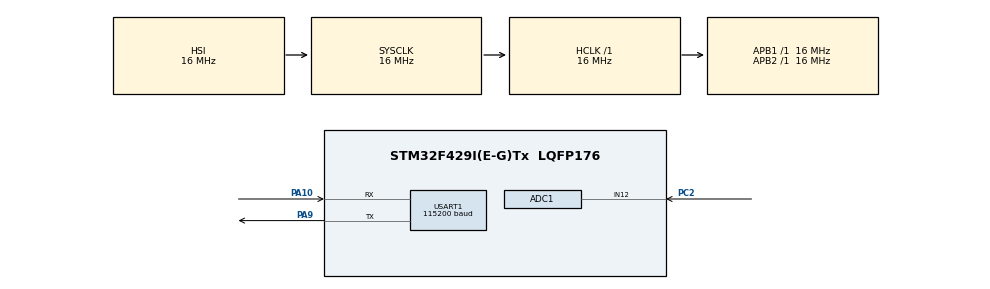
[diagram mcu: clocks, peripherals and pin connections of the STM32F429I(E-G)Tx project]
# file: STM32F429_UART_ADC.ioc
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ADC1.Channel-0\#ChannelRegularConversion=ADC_CHANNEL_12
ADC1.DMAContinuousRequests=ENABLE
ADC1.ExternalTrigConv=ADC_EXTERNALTRIGCONV_T2_TRGO
ADC1.ExternalTrigConvEdge=ADC_EXTERNALTRIGCONVEDGE_RISING
ADC1.NbrOfConversionFlag=1
ADC1.Rank-0\#ChannelRegularConversion=1
ADC1.SamplingTime-0\#ChannelRegularConversion=ADC_SAMPLETIME_84CYCLES
ADC1.master=1
Dma.ADC1.0.Direction=DMA_PERIPH_TO_MEMORY
Dma.ADC1.0.FIFOMode=DMA_FIFOMODE_DISABLE
Dma.ADC1.0.Instance=DMA2_Stream0
Dma.ADC1.0.MemDataAlignment=DMA_MDATAALIGN_HALFWORD
Dma.ADC1.0.MemInc=DMA_MINC_ENABLE
Dma.ADC1.0.Mode=DMA_CIRCULAR
Dma.ADC1.0.PeriphDataAlignment=DMA_PDATAALIGN_HALFWORD
Dma.ADC1.0.PeriphInc=DMA_PINC_DISABLE
Dma.ADC1.0.Priority=DMA_PRIORITY_LOW
Dma.Request0=ADC1
Mcu.Family=STM32F4
Mcu.Name=STM32F429I(E-G)Tx
Mcu.Package=LQFP176
NVIC.ADC_IRQn=true\:0\:0\:false\:false\:true\:true\:true\:true
NVIC.DMA2_Stream0_IRQn=true\:0\:0\:false\:false\:true\:false\:true\:true
NVIC.PriorityGroup=NVIC_PRIORITYGROUP_4
PA10.Mode=Asynchronous
PA10.Signal=USART1_RX
PA13.Mode=Serial_Wire
PA13.Signal=SYS_JTMS-SWDIO
PA14.Mode=Serial_Wire
PA14.Signal=SYS_JTCK-SWCLK
PA9.Mode=Asynchronous
PA9.Signal=USART1_TX
PC2.Signal=ADCx_IN12
ProjectManager.HeapSize=0x200
ProjectManager.StackSize=0x400
ProjectManager.TargetToolchain=MDK-ARM V5.32
RCC.AHBFreq_Value=16000000
RCC.APB1Freq_Value=16000000
RCC.APB2Freq_Value=16000000
RCC.CortexFreq_Value=16000000
RCC.HSE_VALUE=25000000
RCC.HSI_VALUE=16000000
RCC.LSE_VALUE=32768
RCC.SYSCLKFreq_VALUE=16000000
RCC.VCOOutputFreq_Value=192000000
SH.ADCx_IN12.0=ADC1_IN12,IN12
TIM2.Period=999
TIM2.Prescaler=79
TIM2.TIM_MasterOutputTrigger=TIM_TRGO_UPDATE
USART1.BaudRate=115200
USART1.VirtualMode=VM_ASYNC
VP_TIM2_VS_ClockSourceINT.Mode=Internal
board=custom

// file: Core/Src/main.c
/* USER CODE BEGIN Header */
/**
  ******************************************************************************
  * @file           : main.c
  * @brief          : Main program body
  ******************************************************************************
  * @attention
  *
  * Copyright (c) 2026 STMicroelectronics.
  * All rights reserved.
  *
  * This software is licensed under terms that can be found in the LICENSE file
  * in the root directory of this software component.
  * If no LICENSE file comes with this software, it is provided AS-IS.
  *
  ******************************************************************************
  */
/* USER CODE END Header */
#include "main.h"

/* USER CODE BEGIN Includes */
#include <stdbool.h>
#include <stdio.h>
/* USER CODE END Includes */

/* USER CODE BEGIN PTD */
typedef struct
{
  uint32_t index;
  uint16_t raw;
} AdcSample;
/* USER CODE END PTD */

/* USER CODE BEGIN PD */
#define SAMPLE_QUEUE_SIZE    64U
#define ADC_FULL_SCALE      4095U
#define ADC_REFERENCE_MV    3300U
/* USER CODE END PD */

ADC_HandleTypeDef hadc1;
DMA_HandleTypeDef hdma_adc1;

TIM_HandleTypeDef htim2;

UART_HandleTypeDef huart1;

/* USER CODE BEGIN PV */
__ALIGNED(4) static volatile uint16_t dma_samples[2];
static volatile AdcSample sample_queue[SAMPLE_QUEUE_SIZE];
static volatile uint32_t queue_write;
static volatile uint32_t queue_read;
static uint32_t sample_index;
static volatile bool streaming = true;
static volatile bool adc_failed;
/* USER CODE END PV */

void SystemClock_Config(void);
static void MX_GPIO_Init(void);
static void MX_DMA_Init(void);
static void MX_ADC1_Init(void);
static void MX_USART1_UART_Init(void);
static void MX_TIM2_Init(void);

/* USER CODE BEGIN 0 */
/* The DMA callbacks produce samples. The main loop owns UART transmission. */
static void QueueAdcSample(uint16_t raw)
{
  const uint32_t index = sample_index++;
  const uint32_t write = queue_write;

  /* Count every conversion so a full queue leaves a detectable gap. */
  if (streaming && write - queue_read < SAMPLE_QUEUE_SIZE)
  {
    sample_queue[write % SAMPLE_QUEUE_SIZE] = (AdcSample){index, raw};
    queue_write = write + 1U;
  }
}

static void SendAdcSample(AdcSample sample)
{
  const uint32_t millivolts = (sample.raw * ADC_REFERENCE_MV + ADC_FULL_SCALE / 2U) / ADC_FULL_SCALE;
  char row[24];
  const int length = snprintf(row, sizeof(row), "%lu,%u,%u\r\n",
                              (unsigned long)sample.index, (unsigned int)sample.raw,
                              (unsigned int)millivolts);
  if (length > 0 && (size_t)length < sizeof(row))
  {
    HAL_UART_Transmit(&huart1, (uint8_t *)row, (uint16_t)length, 5U);
  }
}
/* USER CODE END 0 */

int main(void)
{

  /* MCU Configuration--------------------------------------------------------*/

  /* Reset of all peripherals, Initializes the Flash interface and the Systick. */
  HAL_Init();

  /* Configure the system clock */
  SystemClock_Config();

  /* Initialize all configured peripherals */
  MX_GPIO_Init();
  MX_DMA_Init();
  MX_ADC1_Init();
  MX_USART1_UART_Init();
  MX_TIM2_Init();
  /* USER CODE BEGIN 2 */
  uint8_t echo_buffer[256];
  if (HAL_ADC_Start_DMA(&hadc1, (uint32_t *)dma_samples, 2U) != HAL_OK ||
      HAL_TIM_Base_Start(&htim2) != HAL_OK)
  {
    Error_Handler();
  }
  /* USER CODE END 2 */

  /* Infinite loop */
  while (1)
  {

    /* USER CODE BEGIN 3 */
    if (adc_failed)
    {
      static uint8_t message[] = "ERR,ADC_DMA\r\n";
      HAL_UART_Transmit(&huart1, message, sizeof(message) - 1U, 10U);
      Error_Handler();
    }

    if (streaming)
    {
      /* Poll for '-' without delaying the next ADC sample. */
      uint8_t command;
      if (HAL_UART_Receive(&huart1, &command, 1U, 0U) == HAL_OK && command == '-')
      {
        streaming = false;
        queue_read = queue_write;
        continue;
      }

      const uint32_t read = queue_read;
      if (read != queue_write)
      {
        const AdcSample sample = sample_queue[read % SAMPLE_QUEUE_SIZE];
        queue_read = read + 1U;
        SendAdcSample(sample);
      }
    }
    else
    {
      /* Receive a short burst, then send back exactly the received bytes. */
      uint16_t length = 0U;
      if (HAL_UARTEx_ReceiveToIdle(&huart1, echo_buffer, sizeof(echo_buffer),
                                 &length, HAL_MAX_DELAY) == HAL_OK)
      {
        if (length == 1U && echo_buffer[0] == '+')
        {
          streaming = true;
        }
        else
        {
          HAL_UART_Transmit(&huart1, echo_buffer, length, 50U);
        }
      }
    }
  }
  /* USER CODE END 3 */
}

void SystemClock_Config(void)
{
  RCC_OscInitTypeDef RCC_OscInitStruct = {0};
  RCC_ClkInitTypeDef RCC_ClkInitStruct = {0};

  /** Configure the main internal regulator output voltage
  */
  __HAL_RCC_PWR_CLK_ENABLE();
  __HAL_PWR_VOLTAGESCALING_CONFIG(PWR_REGULATOR_VOLTAGE_SCALE3);

  /** Initializes the RCC Oscillators according to the specified parameters
  * in the RCC_OscInitTypeDef structure.
  */
  RCC_OscInitStruct.OscillatorType = RCC_OSCILLATORTYPE_HSI;
  RCC_OscInitStruct.HSIState = RCC_HSI_ON;
  RCC_OscInitStruct.HSICalibrationValue = RCC_HSICALIBRATION_DEFAULT;
  RCC_OscInitStruct.PLL.PLLState = RCC_PLL_NONE;
  if (HAL_RCC_OscConfig(&RCC_OscInitStruct) != HAL_OK)
  {
    Error_Handler();
  }

  /** Initializes the CPU, AHB and APB buses clocks
  */
  RCC_ClkInitStruct.ClockType = RCC_CLOCKTYPE_HCLK|RCC_CLOCKTYPE_SYSCLK
                              |RCC_CLOCKTYPE_PCLK1|RCC_CLOCKTYPE_PCLK2;
  RCC_ClkInitStruct.SYSCLKSource = RCC_SYSCLKSOURCE_HSI;
  RCC_ClkInitStruct.AHBCLKDivider = RCC_SYSCLK_DIV1;
  RCC_ClkInitStruct.APB1CLKDivider = RCC_HCLK_DIV1;
  RCC_ClkInitStruct.APB2CLKDivider = RCC_HCLK_DIV1;

  if (HAL_RCC_ClockConfig(&RCC_ClkInitStruct, FLASH_LATENCY_0) != HAL_OK)
  {
    Error_Handler();
  }
}

static void MX_ADC1_Init(void)
{

  ADC_ChannelConfTypeDef sConfig = {0};

  /** Configure the global features of the ADC (Clock, Resolution, Data Alignment and number of conversion)
  */
  hadc1.Instance = ADC1;
  hadc1.Init.ClockPrescaler = ADC_CLOCK_SYNC_PCLK_DIV2;
  hadc1.Init.Resolution = ADC_RESOLUTION_12B;
  hadc1.Init.ScanConvMode = DISABLE;
  hadc1.Init.ContinuousConvMode = DISABLE;
  hadc1.Init.DiscontinuousConvMode = DISABLE;
  hadc1.Init.ExternalTrigConvEdge = ADC_EXTERNALTRIGCONVEDGE_RISING;
  hadc1.Init.ExternalTrigConv = ADC_EXTERNALTRIGCONV_T2_TRGO;
  hadc1.Init.DataAlign = ADC_DATAALIGN_RIGHT;
  hadc1.Init.NbrOfConversion = 1;
  hadc1.Init.DMAContinuousRequests = ENABLE;
  hadc1.Init.EOCSelection = ADC_EOC_SINGLE_CONV;
  if (HAL_ADC_Init(&hadc1) != HAL_OK)
  {
    Error_Handler();
  }

  /** Configure for the selected ADC regular channel its corresponding rank in the sequencer and its sample time.
  */
  sConfig.Channel = ADC_CHANNEL_12;
  sConfig.Rank = 1;
  sConfig.SamplingTime = ADC_SAMPLETIME_84CYCLES;
  if (HAL_ADC_ConfigChannel(&hadc1, &sConfig) != HAL_OK)
  {
    Error_Handler();
  }

}

static void MX_TIM2_Init(void)
{

  TIM_ClockConfigTypeDef sClockSourceConfig = {0};
  TIM_MasterConfigTypeDef sMasterConfig = {0};

  htim2.Instance = TIM2;
  htim2.Init.Prescaler = 79;
  htim2.Init.CounterMode = TIM_COUNTERMODE_UP;
  htim2.Init.Period = 999;
  htim2.Init.ClockDivision = TIM_CLOCKDIVISION_DIV1;
  htim2.Init.AutoReloadPreload = TIM_AUTORELOAD_PRELOAD_DISABLE;
  if (HAL_TIM_Base_Init(&htim2) != HAL_OK)
  {
    Error_Handler();
  }
  sClockSourceConfig.ClockSource = TIM_CLOCKSOURCE_INTERNAL;
  if (HAL_TIM_ConfigClockSource(&htim2, &sClockSourceConfig) != HAL_OK)
  {
    Error_Handler();
  }
  sMasterConfig.MasterOutputTrigger = TIM_TRGO_UPDATE;
  sMasterConfig.MasterSlaveMode = TIM_MASTERSLAVEMODE_DISABLE;
  if (HAL_TIMEx_MasterConfigSynchronization(&htim2, &sMasterConfig) != HAL_OK)
  {
    Error_Handler();
  }

}

static void MX_USART1_UART_Init(void)
{

  huart1.Instance = USART1;
  huart1.Init.BaudRate = 115200;
  huart1.Init.WordLength = UART_WORDLENGTH_8B;
  huart1.Init.StopBits = UART_STOPBITS_1;
  huart1.Init.Parity = UART_PARITY_NONE;
  huart1.Init.Mode = UART_MODE_TX_RX;
  huart1.Init.HwFlowCtl = UART_HWCONTROL_NONE;
  huart1.Init.OverSampling = UART_OVERSAMPLING_16;
  if (HAL_UART_Init(&huart1) != HAL_OK)
  {
    Error_Handler();
  }

}

static void MX_DMA_Init(void)
{

  /* DMA controller clock enable */
  __HAL_RCC_DMA2_CLK_ENABLE();

  /* DMA interrupt init */
  /* DMA2_Stream0_IRQn interrupt configuration */
  HAL_NVIC_SetPriority(DMA2_Stream0_IRQn, 0, 0);
  HAL_NVIC_EnableIRQ(DMA2_Stream0_IRQn);

}

static void MX_GPIO_Init(void)
{

  /* GPIO Ports Clock Enable */
  __HAL_RCC_GPIOC_CLK_ENABLE();
  __HAL_RCC_GPIOA_CLK_ENABLE();

}

/* USER CODE BEGIN 4 */
void HAL_ADC_ConvHalfCpltCallback(ADC_HandleTypeDef *hadc)
{
  if (hadc == &hadc1)
  {
    QueueAdcSample(dma_samples[0]);
  }
}

void HAL_ADC_ConvCpltCallback(ADC_HandleTypeDef *hadc)
{
  if (hadc == &hadc1)
  {
    QueueAdcSample(dma_samples[1]);
  }
}

void HAL_ADC_ErrorCallback(ADC_HandleTypeDef *hadc)
{
  if (hadc == &hadc1)
  {
    adc_failed = true;
  }
}
/* USER CODE END 4 */

void Error_Handler(void)
{
  __disable_irq();
  while (1)
  {
  }
}
